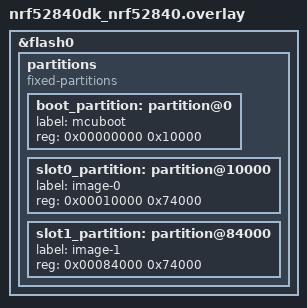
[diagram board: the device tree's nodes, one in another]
/*
 * Copyright 2026 Nordic Semiconductor ASA
 *
 * SPDX-License-Identifier: Apache-2.0
 */

/delete-node/ &boot_partition;
/delete-node/ &slot0_partition;
/delete-node/ &slot1_partition;

&flash0 {
	partitions {
		compatible = "fixed-partitions";
		#address-cells = <1>;
		#size-cells = <1>;

		boot_partition: partition@0 {
			label = "mcuboot";
			reg = <0x00000000 0x10000>;
		};

		slot0_partition: partition@10000 {
			label = "image-0";
			reg = <0x00010000 0x74000>;
		};

		slot1_partition: partition@84000 {
			label = "image-1";
			reg = <0x00084000 0x74000>;
		};
	};
};
